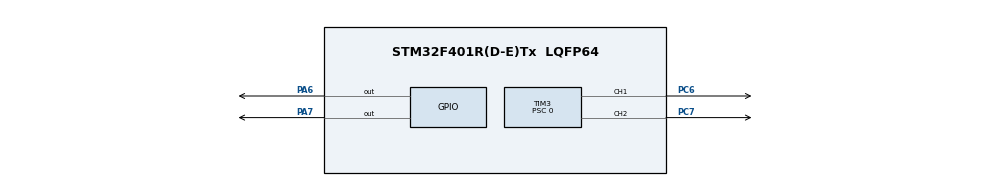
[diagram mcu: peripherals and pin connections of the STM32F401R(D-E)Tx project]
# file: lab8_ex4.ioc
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Mcu.Family=STM32F4
Mcu.Name=STM32F401R(D-E)Tx
Mcu.Package=LQFP64
NVIC.PriorityGroup=NVIC_PRIORITYGROUP_4
PA6.Signal=GPIO_Output
PA7.Signal=GPIO_Output
PC6.Signal=S_TIM3_CH1
PC7.Signal=S_TIM3_CH2
ProjectManager.HeapSize=0x200
ProjectManager.StackSize=0x400
ProjectManager.TargetToolchain=STM32CubeIDE
RCC.48MHZClocksFreq_Value=84000000
RCC.AHBFreq_Value=84000000
RCC.APB1CLKDivider=RCC_HCLK_DIV2
RCC.APB1Freq_Value=42000000
RCC.APB1TimFreq_Value=84000000
RCC.APB2Freq_Value=84000000
RCC.APB2TimFreq_Value=84000000
RCC.CortexFreq_Value=84000000
RCC.HCLKFreq_Value=84000000
RCC.HSE_VALUE=25000000
RCC.HSI_VALUE=16000000
RCC.LSE_VALUE=32768
RCC.PLLN=336
RCC.PLLP=RCC_PLLP_DIV4
RCC.SYSCLKFreq_VALUE=84000000
RCC.SYSCLKSource=RCC_SYSCLKSOURCE_PLLCLK
RCC.VCOOutputFreq_Value=336000000
SH.S_TIM3_CH1.0=TIM3_CH1,Output Compare1 CH1
SH.S_TIM3_CH2.0=TIM3_CH2,Output Compare2 CH2
TIM3.Channel-Output\ Compare1\ CH1=TIM_CHANNEL_1
TIM3.Channel-Output\ Compare2\ CH2=TIM_CHANNEL_2
TIM3.OCMode_1=TIM_OCMODE_TOGGLE
TIM3.OCMode_2=TIM_OCMODE_TOGGLE
TIM3.Period=65535
TIM3.Prescaler=0
VP_TIM3_VS_ClockSourceINT.Mode=Internal
board=custom

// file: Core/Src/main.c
/* USER CODE BEGIN Header */
/**
  ******************************************************************************
  * @file           : main.c
  * @brief          : Main program body
  ******************************************************************************
  * @attention
  *
  * <h2><center>&copy; Copyright (c) 2020 STMicroelectronics.
  * All rights reserved.</center></h2>
  *
  * This software component is licensed by ST under BSD 3-Clause license,
  * the "License"; You may not use this file except in compliance with the
  * License. You may obtain a copy of the License at:
  *                        opensource.org/licenses/BSD-3-Clause
  *
  ******************************************************************************
  */
/* USER CODE END Header */

#include "main.h"
#define HF_PERIOD_1 16800
#define HF_PERIOD_2 3360

void SystemClock_Config(void);
static void MX_GPIO_Init(void);
static void MX_TIM3_Init(void);

int main(void)
{

  /* MCU Configuration--------------------------------------------------------*/

  /* Reset of all peripherals, Initializes the Flash interface and the Systick. */

  LL_APB2_GRP1_EnableClock(LL_APB2_GRP1_PERIPH_SYSCFG);
  LL_APB1_GRP1_EnableClock(LL_APB1_GRP1_PERIPH_PWR);

  NVIC_SetPriorityGrouping(NVIC_PRIORITYGROUP_4);

  /* System interrupt init*/

  /* Configure the system clock */
  SystemClock_Config();

  /* Initialize all configured peripherals */
  MX_GPIO_Init();
  MX_TIM3_Init();
  /* USER CODE BEGIN 2 */
  // enable the counter
  LL_TIM_WriteReg(TIM3 , CR1 , LL_TIM_ReadReg(TIM3 , CR1) | 0x01);
  // ENABLE the ch1 and ch2 pins
  LL_TIM_WriteReg(TIM3 , CCER ,LL_TIM_ReadReg(TIM3 ,CCER) | 0x11);
  // redundant two line however it shows that our two channels are output
  //LL_TIM_WriteReg(TIM3 , CCMR1 ,LL_TIM_ReadReg(TIM3 ,CCMR1) & (~0x3));
  //LL_TIM_WriteReg(TIM3 , CCMR1 ,LL_TIM_ReadReg(TIM3 ,CCMR1) & (~0x300));
  LL_TIM_WriteReg(TIM3 , CCR1, HF_PERIOD_1);
  LL_TIM_WriteReg(TIM3 , CCR2, HF_PERIOD_2);

  unsigned int delta_1 =0 ,delta_2 =0 ;
  SysTick_Config(SystemCoreClock / 1000);
  /* USER CODE END 2 */

  /* Infinite loop */
  /* USER CODE BEGIN WHILE */

  // the output pins for ch1 and ch2 are pc6 and pc7 respectively
  while (1)
  {
    /* USER CODE END WHILE */
	  if((LL_TIM_ReadReg(TIM3 , SR) & 0x02) == 0x02){
		  delta_1 += HF_PERIOD_1;
		  //LL_DBGMCU_APB1_GRP1_FreezePeriph(LL_DBGMCU_APB1_GRP1_TIM3_STOP);
		  LL_TIM_WriteReg(TIM3 ,CCR1 , LL_TIM_ReadReg(TIM3 ,CCR1) + HF_PERIOD_1);
		  //this command writes the content of PC6 into PA6 because PC6 is tim3_ch1 and PA6 is our output peripheral
		  //LL_GPIO_WriteReg(GPIOA ,ODR , LL_GPIO_ReadReg(GPIOA ,ODR) ^ 0x40);
		  LL_GPIO_WriteReg(GPIOA ,ODR , LL_GPIO_ReadReg(GPIOA ,ODR) | ((LL_GPIO_ReadReg(GPIOC ,ODR) & (0x40))));
		  LL_TIM_WriteReg(TIM3 ,SR , LL_TIM_ReadReg(TIM3 , SR) & (~0x02));
	  }
	  if((LL_TIM_ReadReg(TIM3 , SR) & 0x04) == 0x04){
		  delta_2 += HF_PERIOD_2 ;
		  LL_TIM_WriteReg(TIM3 , CCR2, LL_TIM_ReadReg(TIM3 ,CCR2) + HF_PERIOD_2);
		  //LL_GPIO_WriteReg(GPIOA ,ODR , LL_GPIO_ReadReg(GPIOA ,ODR) ^ 0x80);
		  LL_GPIO_WriteReg(GPIOA ,ODR , LL_GPIO_ReadReg(GPIOA ,ODR) | ((LL_GPIO_ReadReg(GPIOC ,ODR) & (0x80))));
		  LL_TIM_WriteReg(TIM3 ,SR , LL_TIM_ReadReg(TIM3 , SR) & (~0x04));

	  }
  }
}

void SystemClock_Config(void)
{
  LL_FLASH_SetLatency(LL_FLASH_LATENCY_2);

   if(LL_FLASH_GetLatency() != LL_FLASH_LATENCY_2)
  {
  Error_Handler();
  }
  LL_PWR_SetRegulVoltageScaling(LL_PWR_REGU_VOLTAGE_SCALE2);
  LL_RCC_HSI_SetCalibTrimming(16);
  LL_RCC_HSI_Enable();

   /* Wait till HSI is ready */
  while(LL_RCC_HSI_IsReady() != 1)
  {

  }
  LL_RCC_PLL_ConfigDomain_SYS(LL_RCC_PLLSOURCE_HSI, LL_RCC_PLLM_DIV_16, 336, LL_RCC_PLLP_DIV_4);
  LL_RCC_PLL_Enable();

   /* Wait till PLL is ready */
  while(LL_RCC_PLL_IsReady() != 1)
  {

  }
  LL_RCC_SetAHBPrescaler(LL_RCC_SYSCLK_DIV_1);
  LL_RCC_SetAPB1Prescaler(LL_RCC_APB1_DIV_2);
  LL_RCC_SetAPB2Prescaler(LL_RCC_APB2_DIV_1);
  LL_RCC_SetSysClkSource(LL_RCC_SYS_CLKSOURCE_PLL);

   /* Wait till System clock is ready */
  while(LL_RCC_GetSysClkSource() != LL_RCC_SYS_CLKSOURCE_STATUS_PLL)
  {

  }
  LL_Init1msTick(84000000);
  LL_SetSystemCoreClock(84000000);
  LL_RCC_SetTIMPrescaler(LL_RCC_TIM_PRESCALER_TWICE);
}

static void MX_TIM3_Init(void)
{

  LL_TIM_InitTypeDef TIM_InitStruct = {0};
  LL_TIM_OC_InitTypeDef TIM_OC_InitStruct = {0};

  LL_GPIO_InitTypeDef GPIO_InitStruct = {0};

  /* Peripheral clock enable */
  LL_APB1_GRP1_EnableClock(LL_APB1_GRP1_PERIPH_TIM3);

  TIM_InitStruct.Prescaler = 0;
  TIM_InitStruct.CounterMode = LL_TIM_COUNTERMODE_UP;
  TIM_InitStruct.Autoreload = 65535;
  TIM_InitStruct.ClockDivision = LL_TIM_CLOCKDIVISION_DIV1;
  LL_TIM_Init(TIM3, &TIM_InitStruct);
  LL_TIM_DisableARRPreload(TIM3);
  LL_TIM_SetClockSource(TIM3, LL_TIM_CLOCKSOURCE_INTERNAL);
  TIM_OC_InitStruct.OCMode = LL_TIM_OCMODE_TOGGLE;
  TIM_OC_InitStruct.OCState = LL_TIM_OCSTATE_DISABLE;
  TIM_OC_InitStruct.OCNState = LL_TIM_OCSTATE_DISABLE;
  TIM_OC_InitStruct.CompareValue = 0;
  TIM_OC_InitStruct.OCPolarity = LL_TIM_OCPOLARITY_HIGH;
  LL_TIM_OC_Init(TIM3, LL_TIM_CHANNEL_CH1, &TIM_OC_InitStruct);
  LL_TIM_OC_DisableFast(TIM3, LL_TIM_CHANNEL_CH1);
  TIM_OC_InitStruct.OCState = LL_TIM_OCSTATE_DISABLE;
  TIM_OC_InitStruct.OCNState = LL_TIM_OCSTATE_DISABLE;
  LL_TIM_OC_Init(TIM3, LL_TIM_CHANNEL_CH2, &TIM_OC_InitStruct);
  LL_TIM_OC_DisableFast(TIM3, LL_TIM_CHANNEL_CH2);
  LL_TIM_SetTriggerOutput(TIM3, LL_TIM_TRGO_RESET);
  LL_TIM_DisableMasterSlaveMode(TIM3);
  LL_AHB1_GRP1_EnableClock(LL_AHB1_GRP1_PERIPH_GPIOC);
  /**TIM3 GPIO Configuration
  PC6   ------> TIM3_CH1
  PC7   ------> TIM3_CH2
  */
  GPIO_InitStruct.Pin = LL_GPIO_PIN_6|LL_GPIO_PIN_7;
  GPIO_InitStruct.Mode = LL_GPIO_MODE_ALTERNATE;
  GPIO_InitStruct.Speed = LL_GPIO_SPEED_FREQ_LOW;
  GPIO_InitStruct.OutputType = LL_GPIO_OUTPUT_PUSHPULL;
  GPIO_InitStruct.Pull = LL_GPIO_PULL_NO;
  GPIO_InitStruct.Alternate = LL_GPIO_AF_2;
  LL_GPIO_Init(GPIOC, &GPIO_InitStruct);

}

static void MX_GPIO_Init(void)
{
  LL_GPIO_InitTypeDef GPIO_InitStruct = {0};

  /* GPIO Ports Clock Enable */
  LL_AHB1_GRP1_EnableClock(LL_AHB1_GRP1_PERIPH_GPIOA);
  LL_AHB1_GRP1_EnableClock(LL_AHB1_GRP1_PERIPH_GPIOC);

  /**/
  LL_GPIO_ResetOutputPin(GPIOA, LL_GPIO_PIN_6|LL_GPIO_PIN_7);

  /**/
  GPIO_InitStruct.Pin = LL_GPIO_PIN_6|LL_GPIO_PIN_7;
  GPIO_InitStruct.Mode = LL_GPIO_MODE_OUTPUT;
  GPIO_InitStruct.Speed = LL_GPIO_SPEED_FREQ_LOW;
  GPIO_InitStruct.OutputType = LL_GPIO_OUTPUT_PUSHPULL;
  GPIO_InitStruct.Pull = LL_GPIO_PULL_NO;
  LL_GPIO_Init(GPIOA, &GPIO_InitStruct);

}

void Error_Handler(void)
{
}

/************************ (C) COPYRIGHT STMicroelectronics *****END OF FILE****/
